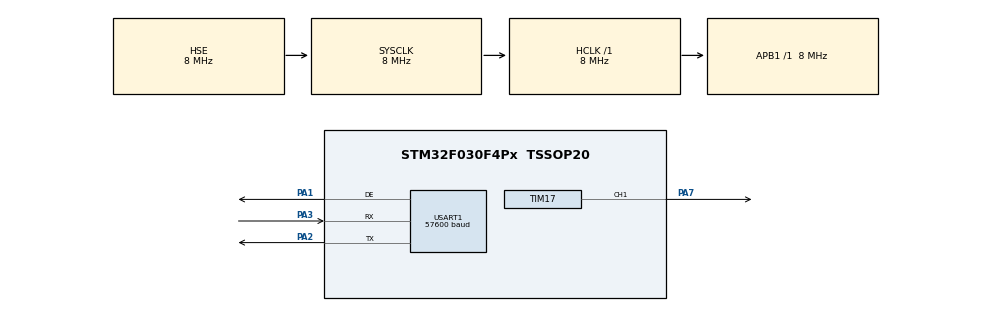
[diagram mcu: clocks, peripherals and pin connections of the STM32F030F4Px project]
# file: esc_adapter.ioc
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Mcu.Family=STM32F0
Mcu.Name=STM32F030F4Px
Mcu.Package=TSSOP20
NVIC.USART1_IRQn=true\:0\:0\:false\:false\:true\:true\:true
PA1.Mode=Hardware Flow Control (RS485)
PA1.Signal=USART1_DE
PA13.Mode=Serial_Wire
PA13.Signal=SYS_SWDIO
PA14.Mode=Serial_Wire
PA14.Signal=SYS_SWCLK
PA2.Mode=Asynchronous
PA2.Signal=USART1_TX
PA3.Mode=Asynchronous
PA3.Signal=USART1_RX
PA7.Signal=S_TIM17_CH1
PF0-OSC_IN.Mode=HSE-External-Oscillator
PF0-OSC_IN.Signal=RCC_OSC_IN
PF1-OSC_OUT.Mode=HSE-External-Oscillator
PF1-OSC_OUT.Signal=RCC_OSC_OUT
ProjectManager.HeapSize=0x200
ProjectManager.StackSize=0x400
ProjectManager.TargetToolchain=STM32CubeIDE
RCC.AHBFreq_Value=8000000
RCC.APB1Freq_Value=8000000
RCC.APB1TimFreq_Value=8000000
RCC.HCLKFreq_Value=8000000
RCC.PLLSourceVirtual=RCC_PLLSOURCE_HSE
RCC.SYSCLKFreq_VALUE=8000000
RCC.SYSCLKSource=RCC_SYSCLKSOURCE_HSE
SH.S_TIM17_CH1.0=TIM17_CH1,PWM Generation1 CH1
TIM17.Channel=TIM_CHANNEL_1
TIM17.Period=6400-1
TIM17.Prescaler=25-1
TIM17.Pulse=480-1
USART1.BaudRate=57600
USART1.VirtualMode-Asynchronous=VM_ASYNC
USART1.VirtualMode-Hardware\ Flow\ Control\ (RS485)=VM_ASYNC
VP_TIM17_VS_ClockSourceINT.Mode=Enable_Timer
board=custom

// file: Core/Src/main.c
/* USER CODE BEGIN Header */
/**
  ******************************************************************************
  * @file           : main.c
  * @brief          : Main program body
  ******************************************************************************
  * @attention
  *
  * Copyright (c) 2021 STMicroelectronics.
  * All rights reserved.
  *
  * This software is licensed under terms that can be found in the LICENSE file
  * in the root directory of this software component.
  * If no LICENSE file comes with this software, it is provided AS-IS.
  *
  ******************************************************************************
  */
/* USER CODE END Header */
#include "main.h"

/* USER CODE BEGIN Includes */
#include "esc_adapter.h"
#include "device.h"
#include "flash.h"
/* USER CODE END Includes */

TIM_HandleTypeDef htim17;

UART_HandleTypeDef huart1;

void SystemClock_Config(void);
static void MX_GPIO_Init(void);
static void MX_USART1_UART_Init(void);
static void MX_TIM17_Init(void);

int main(void)
{

  /* MCU Configuration--------------------------------------------------------*/

  /* Reset of all peripherals, Initializes the Flash interface and the Systick. */
  HAL_Init();

  /* Configure the system clock */
  SystemClock_Config();

  /* Initialize all configured peripherals */
  MX_GPIO_Init();
  MX_USART1_UART_Init();
  MX_TIM17_Init();
  /* USER CODE BEGIN 2 */
  esc_adapter_init();
  /* USER CODE END 2 */

  /* Infinite loop */
  /* USER CODE BEGIN WHILE */
  int last_tic = 0;
  while (1)
  {
    /* USER CODE END WHILE */

    /* USER CODE BEGIN 3 */
    esc_adapter_loop();
  }
  /* USER CODE END 3 */
}

void SystemClock_Config(void)
{
  RCC_OscInitTypeDef RCC_OscInitStruct = {0};
  RCC_ClkInitTypeDef RCC_ClkInitStruct = {0};
  RCC_PeriphCLKInitTypeDef PeriphClkInit = {0};

  /** Initializes the RCC Oscillators according to the specified parameters
  * in the RCC_OscInitTypeDef structure.
  */
  RCC_OscInitStruct.OscillatorType = RCC_OSCILLATORTYPE_HSE;
  RCC_OscInitStruct.HSEState = RCC_HSE_ON;
  RCC_OscInitStruct.PLL.PLLState = RCC_PLL_NONE;
  if (HAL_RCC_OscConfig(&RCC_OscInitStruct) != HAL_OK)
  {
    Error_Handler();
  }
  /** Initializes the CPU, AHB and APB buses clocks
  */
  RCC_ClkInitStruct.ClockType = RCC_CLOCKTYPE_HCLK|RCC_CLOCKTYPE_SYSCLK
                              |RCC_CLOCKTYPE_PCLK1;
  RCC_ClkInitStruct.SYSCLKSource = RCC_SYSCLKSOURCE_HSE;
  RCC_ClkInitStruct.AHBCLKDivider = RCC_SYSCLK_DIV1;
  RCC_ClkInitStruct.APB1CLKDivider = RCC_HCLK_DIV1;

  if (HAL_RCC_ClockConfig(&RCC_ClkInitStruct, FLASH_LATENCY_0) != HAL_OK)
  {
    Error_Handler();
  }
  PeriphClkInit.PeriphClockSelection = RCC_PERIPHCLK_USART1;
  PeriphClkInit.Usart1ClockSelection = RCC_USART1CLKSOURCE_PCLK1;
  if (HAL_RCCEx_PeriphCLKConfig(&PeriphClkInit) != HAL_OK)
  {
    Error_Handler();
  }
}

static void MX_TIM17_Init(void)
{

  TIM_OC_InitTypeDef sConfigOC = {0};
  TIM_BreakDeadTimeConfigTypeDef sBreakDeadTimeConfig = {0};

  htim17.Instance = TIM17;
  htim17.Init.Prescaler = 25-1;
  htim17.Init.CounterMode = TIM_COUNTERMODE_UP;
  htim17.Init.Period = 6400-1;
  htim17.Init.ClockDivision = TIM_CLOCKDIVISION_DIV1;
  htim17.Init.RepetitionCounter = 0;
  htim17.Init.AutoReloadPreload = TIM_AUTORELOAD_PRELOAD_DISABLE;
  if (HAL_TIM_Base_Init(&htim17) != HAL_OK)
  {
    Error_Handler();
  }
  if (HAL_TIM_PWM_Init(&htim17) != HAL_OK)
  {
    Error_Handler();
  }
  sConfigOC.OCMode = TIM_OCMODE_PWM1;
  sConfigOC.Pulse = 480-1;
  sConfigOC.OCPolarity = TIM_OCPOLARITY_HIGH;
  sConfigOC.OCNPolarity = TIM_OCNPOLARITY_HIGH;
  sConfigOC.OCFastMode = TIM_OCFAST_DISABLE;
  sConfigOC.OCIdleState = TIM_OCIDLESTATE_RESET;
  sConfigOC.OCNIdleState = TIM_OCNIDLESTATE_RESET;
  if (HAL_TIM_PWM_ConfigChannel(&htim17, &sConfigOC, TIM_CHANNEL_1) != HAL_OK)
  {
    Error_Handler();
  }
  sBreakDeadTimeConfig.OffStateRunMode = TIM_OSSR_DISABLE;
  sBreakDeadTimeConfig.OffStateIDLEMode = TIM_OSSI_DISABLE;
  sBreakDeadTimeConfig.LockLevel = TIM_LOCKLEVEL_OFF;
  sBreakDeadTimeConfig.DeadTime = 0;
  sBreakDeadTimeConfig.BreakState = TIM_BREAK_DISABLE;
  sBreakDeadTimeConfig.BreakPolarity = TIM_BREAKPOLARITY_HIGH;
  sBreakDeadTimeConfig.AutomaticOutput = TIM_AUTOMATICOUTPUT_DISABLE;
  if (HAL_TIMEx_ConfigBreakDeadTime(&htim17, &sBreakDeadTimeConfig) != HAL_OK)
  {
    Error_Handler();
  }
  HAL_TIM_MspPostInit(&htim17);

}

static void MX_USART1_UART_Init(void)
{

  huart1.Instance = USART1;
  huart1.Init.BaudRate = 57600;
  huart1.Init.WordLength = UART_WORDLENGTH_8B;
  huart1.Init.StopBits = UART_STOPBITS_1;
  huart1.Init.Parity = UART_PARITY_NONE;
  huart1.Init.Mode = UART_MODE_TX_RX;
  huart1.Init.HwFlowCtl = UART_HWCONTROL_NONE;
  huart1.Init.OverSampling = UART_OVERSAMPLING_16;
  huart1.Init.OneBitSampling = UART_ONE_BIT_SAMPLE_DISABLE;
  huart1.AdvancedInit.AdvFeatureInit = UART_ADVFEATURE_NO_INIT;
  if (HAL_RS485Ex_Init(&huart1, UART_DE_POLARITY_HIGH, 0, 0) != HAL_OK)
  {
    Error_Handler();
  }

}

static void MX_GPIO_Init(void)
{

  /* GPIO Ports Clock Enable */
  __HAL_RCC_GPIOF_CLK_ENABLE();
  __HAL_RCC_GPIOA_CLK_ENABLE();

}

void Error_Handler(void)
{
  __disable_irq();
  while (1)
  {
  }
}
